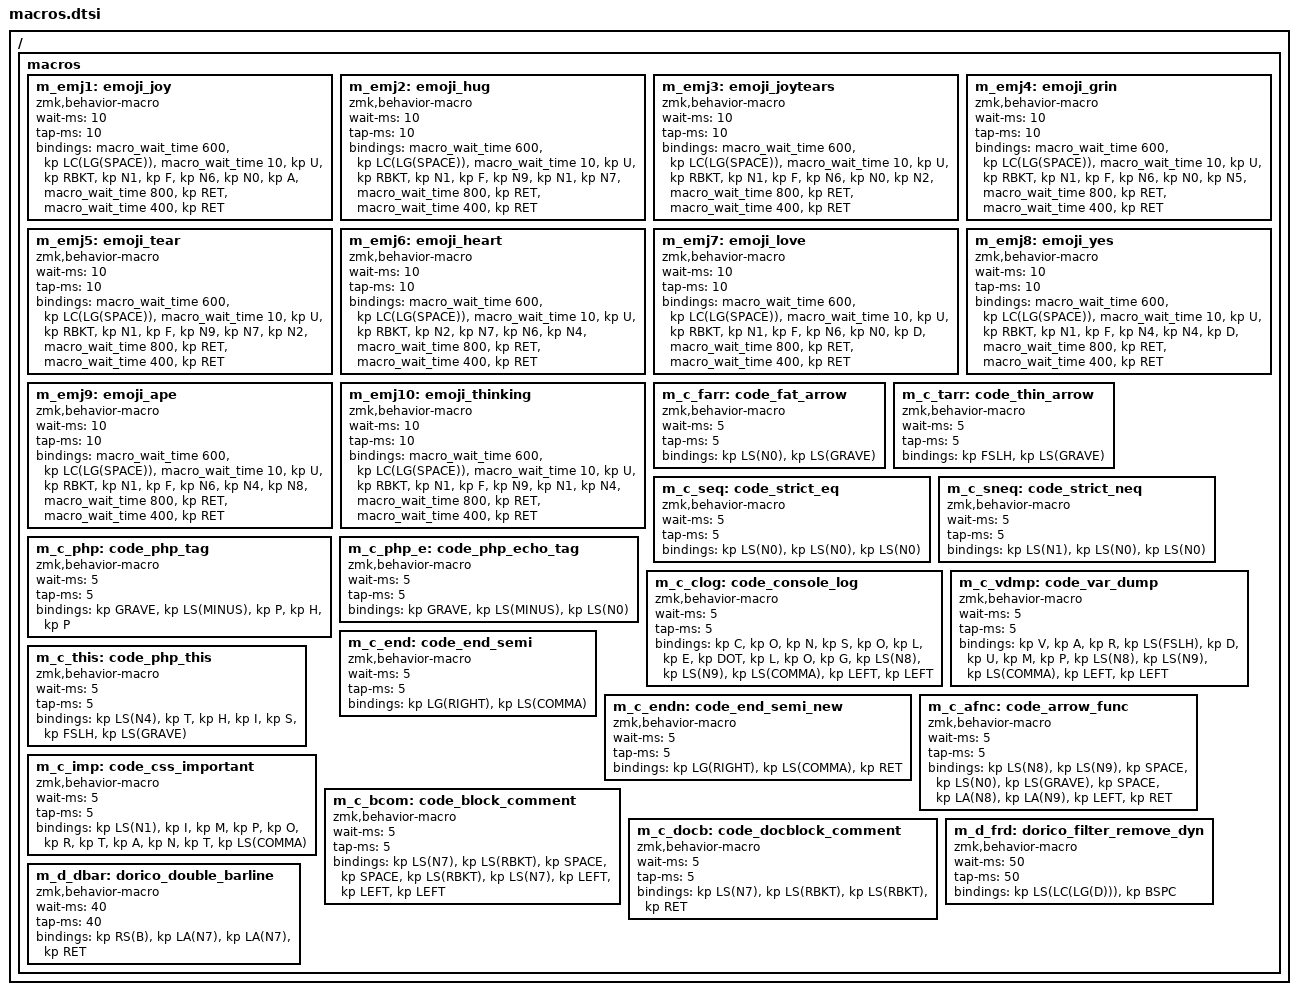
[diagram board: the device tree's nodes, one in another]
/ {
    macros {
        // ---------------- EMOJIS ----------------
	    m_emj1: emoji_joy {
               compatible = "zmk,behavior-macro";
               #binding-cells = <0>;
               wait-ms = <10>;
               tap-ms = <10>;
               bindings =
                   <&macro_wait_time 600>,
                   <&kp LC(LG(SPACE))>,
                   <&macro_wait_time 10>,
                   <&kp U &kp RBKT &kp N1 &kp F &kp N6 &kp N0 &kp A>,
                   <&macro_wait_time 800>,
                   <&kp RET>,
                   <&macro_wait_time 400>,
                   <&kp RET>;
        };
        m_emj2: emoji_hug {
               compatible = "zmk,behavior-macro";
               #binding-cells = <0>;
               wait-ms = <10>;
               tap-ms = <10>;
               bindings =
                   <&macro_wait_time 600>,
                   <&kp LC(LG(SPACE))>,
                   <&macro_wait_time 10>,
                   <&kp U &kp RBKT &kp N1 &kp F &kp N9 &kp N1 &kp N7>,
                   <&macro_wait_time 800>,
                   <&kp RET>,
                   <&macro_wait_time 400>,
                   <&kp RET>;
        };
        m_emj3: emoji_joytears {
               compatible = "zmk,behavior-macro";
               #binding-cells = <0>;
               wait-ms = <10>;
               tap-ms = <10>;
               bindings =
                   <&macro_wait_time 600>,
                   <&kp LC(LG(SPACE))>,
                   <&macro_wait_time 10>,
                   <&kp U &kp RBKT &kp N1 &kp F &kp N6 &kp N0 &kp N2>,
                   <&macro_wait_time 800>,
                   <&kp RET>,
                   <&macro_wait_time 400>,
                   <&kp RET>;
        };
        m_emj4: emoji_grin {
               compatible = "zmk,behavior-macro";
               #binding-cells = <0>;
               wait-ms = <10>;
               tap-ms = <10>;
               bindings =
                   <&macro_wait_time 600>,
                   <&kp LC(LG(SPACE))>,
                   <&macro_wait_time 10>,
                   <&kp U &kp RBKT &kp N1 &kp F &kp N6 &kp N0 &kp N5>,
                   <&macro_wait_time 800>,
                   <&kp RET>,
                   <&macro_wait_time 400>,
                   <&kp RET>;
        };
        m_emj5: emoji_tear {
               compatible = "zmk,behavior-macro";
               #binding-cells = <0>;
               wait-ms = <10>;
               tap-ms = <10>;
               bindings =
                   <&macro_wait_time 600>,
                   <&kp LC(LG(SPACE))>,
                   <&macro_wait_time 10>,
                   <&kp U &kp RBKT &kp N1 &kp F &kp N9 &kp N7 &kp N2>,
                   <&macro_wait_time 800>,
                   <&kp RET>,
                   <&macro_wait_time 400>,
                   <&kp RET>;
        };
        m_emj6: emoji_heart {
               compatible = "zmk,behavior-macro";
               #binding-cells = <0>;
               wait-ms = <10>;
               tap-ms = <10>;
               bindings =
                   <&macro_wait_time 600>,
                   <&kp LC(LG(SPACE))>,
                   <&macro_wait_time 10>,
                   <&kp U &kp RBKT &kp N2 &kp N7 &kp N6 &kp N4>,
                   <&macro_wait_time 800>,
                   <&kp RET>,
                   <&macro_wait_time 400>,
                   <&kp RET>;
        };
        m_emj7: emoji_love {
               compatible = "zmk,behavior-macro";
               #binding-cells = <0>;
               wait-ms = <10>;
               tap-ms = <10>;
               bindings =
                   <&macro_wait_time 600>,
                   <&kp LC(LG(SPACE))>,
                   <&macro_wait_time 10>,
                   <&kp U &kp RBKT &kp N1 &kp F &kp N6 &kp N0 &kp D>,
                   <&macro_wait_time 800>,
                   <&kp RET>,
                   <&macro_wait_time 400>,
                   <&kp RET>;
        };
        m_emj8: emoji_yes {
               compatible = "zmk,behavior-macro";
               #binding-cells = <0>;
               wait-ms = <10>;
               tap-ms = <10>;
               bindings =
                   <&macro_wait_time 600>,
                   <&kp LC(LG(SPACE))>,
                   <&macro_wait_time 10>,
                   <&kp U &kp RBKT &kp N1 &kp F &kp N4 &kp N4 &kp D>,
                   <&macro_wait_time 800>,
                   <&kp RET>,
                   <&macro_wait_time 400>,
                   <&kp RET>;
        };
        m_emj9: emoji_ape {
               compatible = "zmk,behavior-macro";
               #binding-cells = <0>;
               wait-ms = <10>;
               tap-ms = <10>;
               bindings =
                   <&macro_wait_time 600>,
                   <&kp LC(LG(SPACE))>,
                   <&macro_wait_time 10>,
                   <&kp U &kp RBKT &kp N1 &kp F &kp N6 &kp N4 &kp N8>,
                   <&macro_wait_time 800>,
                   <&kp RET>,
                   <&macro_wait_time 400>,
                   <&kp RET>;
        };
        m_emj10: emoji_thinking {
               compatible = "zmk,behavior-macro";
               #binding-cells = <0>;
               wait-ms = <10>;
               tap-ms = <10>;
               bindings =
                   <&macro_wait_time 600>,
                   <&kp LC(LG(SPACE))>,
                   <&macro_wait_time 10>,
                   <&kp U &kp RBKT &kp N1 &kp F &kp N9 &kp N1 &kp N4>,
                   <&macro_wait_time 800>,
                   <&kp RET>,
                   <&macro_wait_time 400>,
                   <&kp RET>;
        };m_emj1: emoji_joy {
               compatible = "zmk,behavior-macro";
               #binding-cells = <0>;
               wait-ms = <10>;
               tap-ms = <10>;
               bindings =
                   <&macro_wait_time 600>,
                   <&kp LC(LG(SPACE))>,
                   <&macro_wait_time 10>,
                   <&kp U &kp RBKT &kp N1 &kp F &kp N6 &kp N0 &kp A>,
                   <&macro_wait_time 800>,
                   <&kp RET>,
                   <&macro_wait_time 400>,
                   <&kp RET>;
        };
        m_emj2: emoji_hug {
               compatible = "zmk,behavior-macro";
               #binding-cells = <0>;
               wait-ms = <10>;
               tap-ms = <10>;
               bindings =
                   <&macro_wait_time 600>,
                   <&kp LC(LG(SPACE))>,
                   <&macro_wait_time 10>,
                   <&kp U &kp RBKT &kp N1 &kp F &kp N9 &kp N1 &kp N7>,
                   <&macro_wait_time 800>,
                   <&kp RET>,
                   <&macro_wait_time 400>,
                   <&kp RET>;
        };
        m_emj3: emoji_joytears {
               compatible = "zmk,behavior-macro";
               #binding-cells = <0>;
               wait-ms = <10>;
               tap-ms = <10>;
               bindings =
                   <&macro_wait_time 600>,
                   <&kp LC(LG(SPACE))>,
                   <&macro_wait_time 10>,
                   <&kp U &kp RBKT &kp N1 &kp F &kp N6 &kp N0 &kp N2>,
                   <&macro_wait_time 800>,
                   <&kp RET>,
                   <&macro_wait_time 400>,
                   <&kp RET>;
        };
        m_emj4: emoji_grin {
               compatible = "zmk,behavior-macro";
               #binding-cells = <0>;
               wait-ms = <10>;
               tap-ms = <10>;
               bindings =
                   <&macro_wait_time 600>,
                   <&kp LC(LG(SPACE))>,
                   <&macro_wait_time 10>,
                   <&kp U &kp RBKT &kp N1 &kp F &kp N6 &kp N0 &kp N5>,
                   <&macro_wait_time 800>,
                   <&kp RET>,
                   <&macro_wait_time 400>,
                   <&kp RET>;
        };
        m_emj5: emoji_tear {
               compatible = "zmk,behavior-macro";
               #binding-cells = <0>;
               wait-ms = <10>;
               tap-ms = <10>;
               bindings =
                   <&macro_wait_time 600>,
                   <&kp LC(LG(SPACE))>,
                   <&macro_wait_time 10>,
                   <&kp U &kp RBKT &kp N1 &kp F &kp N9 &kp N7 &kp N2>,
                   <&macro_wait_time 800>,
                   <&kp RET>,
                   <&macro_wait_time 400>,
                   <&kp RET>;
        };
        m_emj6: emoji_heart {
               compatible = "zmk,behavior-macro";
               #binding-cells = <0>;
               wait-ms = <10>;
               tap-ms = <10>;
               bindings =
                   <&macro_wait_time 600>,
                   <&kp LC(LG(SPACE))>,
                   <&macro_wait_time 10>,
                   <&kp U &kp RBKT &kp N2 &kp N7 &kp N6 &kp N4>,
                   <&macro_wait_time 800>,
                   <&kp RET>,
                   <&macro_wait_time 400>,
                   <&kp RET>;
        };
        m_emj7: emoji_love {
               compatible = "zmk,behavior-macro";
               #binding-cells = <0>;
               wait-ms = <10>;
               tap-ms = <10>;
               bindings =
                   <&macro_wait_time 600>,
                   <&kp LC(LG(SPACE))>,
                   <&macro_wait_time 10>,
                   <&kp U &kp RBKT &kp N1 &kp F &kp N6 &kp N0 &kp D>,
                   <&macro_wait_time 800>,
                   <&kp RET>,
                   <&macro_wait_time 400>,
                   <&kp RET>;
        };
        m_emj8: emoji_yes {
               compatible = "zmk,behavior-macro";
               #binding-cells = <0>;
               wait-ms = <10>;
               tap-ms = <10>;
               bindings =
                   <&macro_wait_time 600>,
                   <&kp LC(LG(SPACE))>,
                   <&macro_wait_time 10>,
                   <&kp U &kp RBKT &kp N1 &kp F &kp N4 &kp N4 &kp D>,
                   <&macro_wait_time 800>,
                   <&kp RET>,
                   <&macro_wait_time 400>,
                   <&kp RET>;
        };
        m_emj9: emoji_ape {
               compatible = "zmk,behavior-macro";
               #binding-cells = <0>;
               wait-ms = <10>;
               tap-ms = <10>;
               bindings =
                   <&macro_wait_time 600>,
                   <&kp LC(LG(SPACE))>,
                   <&macro_wait_time 10>,
                   <&kp U &kp RBKT &kp N1 &kp F &kp N6 &kp N4 &kp N8>,
                   <&macro_wait_time 800>,
                   <&kp RET>,
                   <&macro_wait_time 400>,
                   <&kp RET>;
        };
        m_emj10: emoji_thinking {
               compatible = "zmk,behavior-macro";
               #binding-cells = <0>;
               wait-ms = <10>;
               tap-ms = <10>;
               bindings =
                   <&macro_wait_time 600>,
                   <&kp LC(LG(SPACE))>,
                   <&macro_wait_time 10>,
                   <&kp U &kp RBKT &kp N1 &kp F &kp N9 &kp N1 &kp N4>,
                   <&macro_wait_time 800>,
                   <&kp RET>,
                   <&macro_wait_time 400>,
                   <&kp RET>;
        };

        // ---------------- CODING ----------------

        // 1. Fat Arrow (=>) for JS/TS/PHP
        // Types: = (LS(N0)) then > (LS(GRAVE))
        m_c_farr: code_fat_arrow {
            compatible = "zmk,behavior-macro";
            #binding-cells = <0>;
            wait-ms = <5>; tap-ms = <5>;
            bindings = <&kp LS(N0) &kp LS(GRAVE)>;
        };

        // 2. Thin Arrow (->) for PHP/Dart
        // Types: - (FSLH) then > (LS(GRAVE))
        m_c_tarr: code_thin_arrow {
            compatible = "zmk,behavior-macro";
            #binding-cells = <0>;
            wait-ms = <5>; tap-ms = <5>;
            bindings = <&kp FSLH &kp LS(GRAVE)>;
        };

        // 3. Strict Equality (===) for JS/TS/PHP
        m_c_seq: code_strict_eq {
            compatible = "zmk,behavior-macro";
            #binding-cells = <0>;
            wait-ms = <5>; tap-ms = <5>;
            bindings = <&kp LS(N0) &kp LS(N0) &kp LS(N0)>;
        };

        // 4. Strict Not Equal (!==) for JS/TS/PHP
        // Types: ! (LS(N1)) then ==
        m_c_sneq: code_strict_neq {
            compatible = "zmk,behavior-macro";
            #binding-cells = <0>;
            wait-ms = <5>; tap-ms = <5>;
            bindings = <&kp LS(N1) &kp LS(N0) &kp LS(N0)>;
        };

        // 5a. PHP Tag (<?php)
        // Types: < (GRAVE), ? (LS(MINUS)), p h p
        m_c_php: code_php_tag {
            compatible = "zmk,behavior-macro";
            #binding-cells = <0>;
            wait-ms = <5>; tap-ms = <5>;
            bindings = <&kp GRAVE &kp LS(MINUS) &kp P &kp H &kp P>;
        };

        // 5b. PHP Fast Echo Tag (<?= )
        // Types: < (GRAVE), ? (LS(MINUS)), = (LS(N0))
        m_c_php_e: code_php_echo_tag {
            compatible = "zmk,behavior-macro";
            #binding-cells = <0>;
            wait-ms = <5>; tap-ms = <5>;
            bindings = <&kp GRAVE &kp LS(MINUS) &kp LS(N0)>;
        };
        // 6. Console Log (JS/TS) -> console.log() and puts cursor inside ()
        // Note: () are LS(N8) and LS(N9)
        m_c_clog: code_console_log {
            compatible = "zmk,behavior-macro";
            #binding-cells = <0>;
            wait-ms = <5>; tap-ms = <5>;
            bindings = <&kp C &kp O &kp N &kp S &kp O &kp L &kp E &kp DOT &kp L &kp O &kp G &kp LS(N8) &kp LS(N9) &kp LS(COMMA) &kp LEFT &kp LEFT>;
        };

        // 7. Var Dump (PHP) -> var_dump() and puts cursor inside ()
        // Note: _ is LS(FSLH)
        m_c_vdmp: code_var_dump {
            compatible = "zmk,behavior-macro";
            #binding-cells = <0>;
            wait-ms = <5>; tap-ms = <5>;
            bindings = <&kp V &kp A &kp R &kp LS(FSLH) &kp D &kp U &kp M &kp P &kp LS(N8) &kp LS(N9) &kp LS(COMMA) &kp LEFT &kp LEFT>;
        };

        // 8. End Line & Semicolon
        // Jumps to the end of the current line and adds a ; (LS(COMMA))
        m_c_end: code_end_semi {
            compatible = "zmk,behavior-macro";
            #binding-cells = <0>;
            wait-ms = <5>; tap-ms = <5>;
            bindings = <&kp LG(RIGHT) &kp LS(COMMA)>;
        };

        // 9. End Line, Semicolon, & New Line
        // Same as above, but instantly drops you to the next line ready to type
        m_c_endn: code_end_semi_new {
            compatible = "zmk,behavior-macro";
            #binding-cells = <0>;
            wait-ms = <5>; tap-ms = <5>;
            bindings = <&kp LG(RIGHT) &kp LS(COMMA) &kp RET>;
        };

        // 10. PHP Object Operator ($this->)
        // Highly used in OOP PHP.
        // Types: $ (LS(N4)), t, h, i, s, - (FSLH), > (LS(GRAVE))
        m_c_this: code_php_this {
            compatible = "zmk,behavior-macro";
            #binding-cells = <0>;
            wait-ms = <5>; tap-ms = <5>;
            bindings = <&kp LS(N4) &kp T &kp H &kp I &kp S &kp FSLH &kp LS(GRAVE)>;
        };

        // 11. JS/TS Arrow Function (() => {})
        // Types the full arrow function and places your cursor cleanly inside the braces.
        m_c_afnc: code_arrow_func {
            compatible = "zmk,behavior-macro";
            #binding-cells = <0>;
            wait-ms = <5>; tap-ms = <5>;
            bindings = <&kp LS(N8) &kp LS(N9) &kp SPACE &kp LS(N0) &kp LS(GRAVE) &kp SPACE &kp LA(N8) &kp LA(N9) &kp LEFT &kp RET>;
        };

        // 12. CSS !important
        // Types !important; (great to throw on a single key when debugging CSS).
        // Types: ! (LS(N1))
        m_c_imp: code_css_important {
            compatible = "zmk,behavior-macro";
            #binding-cells = <0>;
            wait-ms = <5>; tap-ms = <5>;
            bindings = <&kp LS(N1) &kp I &kp M &kp P &kp O &kp R &kp T &kp A &kp N &kp T &kp LS(COMMA)>;
        };

        // 13. Block Comment (/* */)
        // Types the comment block and puts your cursor in the middle.
        // / is LS(N7), * is LS(RBKT)
        m_c_bcom: code_block_comment {
            compatible = "zmk,behavior-macro";
            #binding-cells = <0>;
            wait-ms = <5>; tap-ms = <5>;
            bindings = <&kp LS(N7) &kp LS(RBKT) &kp SPACE &kp SPACE &kp LS(RBKT) &kp LS(N7) &kp LEFT &kp LEFT &kp LEFT>;
        };

        // 14. Doc Block Beginning (/** + Enter
        // Types the beginning of a doc block and hits Enter, IDE will autocomplete
        m_c_docb: code_docblock_comment {
            compatible = "zmk,behavior-macro";
            #binding-cells = <0>;
            wait-ms = <5>; tap-ms = <5>;
            bindings = <&kp LS(N7) &kp LS(RBKT) &kp LS(RBKT) &kp RET>;
        };

        // ---------------- DORICO ----------------

        // 1. Filter All Dynamics and Remove them
        m_d_frd: dorico_filter_remove_dyn {
            compatible = "zmk,behavior-macro";
            #binding-cells = <0>;
            wait-ms = <50>; tap-ms = <50>;
            bindings = <&kp LS(LC(LG(D))) &kp BSPC>;
        };

        // 2. Double Barline (||)
        // Opens popover (RS + B), types two pipes (Option + 7 on DE-Mac), and hits Enter
        m_d_dbar: dorico_double_barline {
            compatible = "zmk,behavior-macro";
            #binding-cells = <0>;
            wait-ms = <40>;
            tap-ms = <40>;
            bindings = <&kp RS(B) &kp LA(N7) &kp LA(N7) &kp RET>;
        };

    };
};
